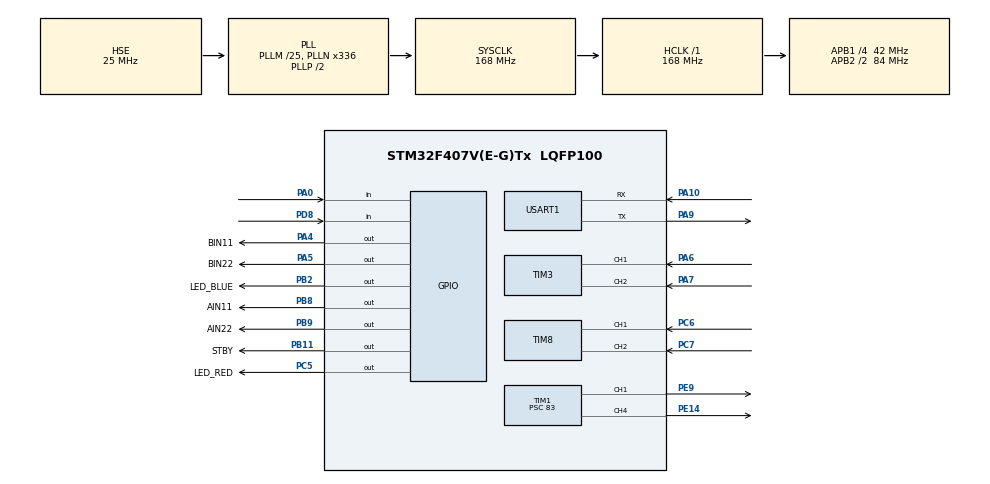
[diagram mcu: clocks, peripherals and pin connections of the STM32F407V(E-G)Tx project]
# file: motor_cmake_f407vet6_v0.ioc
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Mcu.Family=STM32F4
Mcu.Name=STM32F407V(E-G)Tx
Mcu.Package=LQFP100
NVIC.PriorityGroup=NVIC_PRIORITYGROUP_4
NVIC.TIM1_CC_IRQn=true\:0\:0\:false\:false\:true\:true\:true\:true
NVIC.TIM1_UP_TIM10_IRQn=true\:0\:0\:false\:false\:true\:true\:true\:true
NVIC.TIM3_IRQn=true\:0\:0\:false\:false\:true\:true\:true\:true
NVIC.TIM4_IRQn=true\:0\:0\:false\:false\:true\:true\:true\:true
NVIC.TIM8_BRK_TIM12_IRQn=true\:0\:0\:false\:false\:true\:true\:true\:true
NVIC.TIM8_CC_IRQn=true\:0\:0\:false\:false\:true\:true\:true\:true
NVIC.TIM8_TRG_COM_TIM14_IRQn=true\:0\:0\:false\:false\:true\:true\:true\:true
NVIC.TIM8_UP_TIM13_IRQn=true\:0\:0\:false\:false\:true\:true\:true\:true
NVIC.USART1_IRQn=true\:0\:0\:false\:false\:true\:true\:true\:true
PA0-WKUP.GPIO_PuPd=GPIO_NOPULL
PA0-WKUP.Signal=GPIO_Input
PA10.Mode=Asynchronous
PA10.Signal=USART1_RX
PA13.Mode=Serial_Wire
PA13.Signal=SYS_JTMS-SWDIO
PA14.Mode=Serial_Wire
PA14.Signal=SYS_JTCK-SWCLK
PA4.GPIO_Label=BIN11
PA4.Signal=GPIO_Output
PA5.GPIO_Label=BIN22
PA5.Signal=GPIO_Output
PA6.Signal=S_TIM3_CH1
PA7.Signal=S_TIM3_CH2
PA9.Mode=Asynchronous
PA9.Signal=USART1_TX
PB11.GPIO_Label=STBY
PB11.Signal=GPIO_Output
PB2.GPIO_Label=LED_BLUE
PB2.Signal=GPIO_Output
PB8.GPIO_Label=AIN11
PB8.Signal=GPIO_Output
PB9.GPIO_Label=AIN22
PB9.Signal=GPIO_Output
PC5.GPIO_Label=LED_RED
PC5.Signal=GPIO_Output
PC6.Signal=S_TIM8_CH1
PC7.Signal=S_TIM8_CH2
PD8.Signal=GPIO_Input
PE14.Signal=S_TIM1_CH4
PE9.Signal=S_TIM1_CH1
PH0-OSC_IN.Mode=HSE-External-Oscillator
PH0-OSC_IN.Signal=RCC_OSC_IN
PH1-OSC_OUT.Mode=HSE-External-Oscillator
PH1-OSC_OUT.Signal=RCC_OSC_OUT
ProjectManager.HeapSize=0x200
ProjectManager.StackSize=0x400
ProjectManager.TargetToolchain=CMake
RCC.48MHZClocksFreq_Value=84000000
RCC.AHBFreq_Value=168000000
RCC.APB1CLKDivider=RCC_HCLK_DIV4
RCC.APB1Freq_Value=42000000
RCC.APB1TimFreq_Value=84000000
RCC.APB2CLKDivider=RCC_HCLK_DIV2
RCC.APB2Freq_Value=84000000
RCC.APB2TimFreq_Value=168000000
RCC.CortexFreq_Value=168000000
RCC.HCLKFreq_Value=168000000
RCC.HSE_VALUE=25000000
RCC.HSI_VALUE=16000000
RCC.LSE_VALUE=32768
RCC.PLLM=25
RCC.PLLN=336
RCC.PLLSourceVirtual=RCC_PLLSOURCE_HSE
RCC.SYSCLKFreq_VALUE=168000000
RCC.SYSCLKSource=RCC_SYSCLKSOURCE_PLLCLK
RCC.VCOOutputFreq_Value=336000000
SH.S_TIM1_CH1.0=TIM1_CH1,PWM Generation1 CH1
SH.S_TIM1_CH4.0=TIM1_CH4,PWM Generation4 CH4
SH.S_TIM3_CH1.0=TIM3_CH1,Encoder_Interface
SH.S_TIM3_CH2.0=TIM3_CH2,Encoder_Interface
SH.S_TIM8_CH1.0=TIM8_CH1,Encoder_Interface
SH.S_TIM8_CH2.0=TIM8_CH2,Encoder_Interface
TIM1.AutoReloadPreload=TIM_AUTORELOAD_PRELOAD_ENABLE
TIM1.Channel-PWM\ Generation1\ CH1=TIM_CHANNEL_1
TIM1.Channel-PWM\ Generation4\ CH4=TIM_CHANNEL_4
TIM1.Period=999
TIM1.Prescaler=83
TIM3.AutoReloadPreload=TIM_AUTORELOAD_PRELOAD_ENABLE
TIM3.EncoderMode=TIM_ENCODERMODE_TI12
TIM4.Period=9999
TIM4.Prescaler=16799
TIM8.EncoderMode=TIM_ENCODERMODE_TI12
USART1.VirtualMode=VM_ASYNC
VP_TIM1_VS_ClockSourceINT.Mode=Internal
VP_TIM4_VS_ClockSourceINT.Mode=Internal
board=custom

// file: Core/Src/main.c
/* USER CODE BEGIN Header */
/**
 ******************************************************************************
 * @file           : main.c
 * @brief          : Main program body
 ******************************************************************************
 * @attention
 *
 * Copyright (c) 2025 STMicroelectronics.
 * All rights reserved.
 *
 * This software is licensed under terms that can be found in the LICENSE file
 * in the root directory of this software component.
 * If no LICENSE file comes with this software, it is provided AS-IS.
 *
 ******************************************************************************
 */
/* USER CODE END Header */
#include "main.h"
#include "tim.h"
#include "usart.h"
#include "gpio.h"

/* USER CODE BEGIN Includes */
#include "mymain.h"

/* USER CODE END Includes */

void SystemClock_Config(void);

int main(void)
{

    /* MCU Configuration--------------------------------------------------------*/

    /* Reset of all peripherals, Initializes the Flash interface and the Systick. */
    HAL_Init();

    /* Configure the system clock */
    SystemClock_Config();

    /* Initialize all configured peripherals */
    MX_GPIO_Init();
    MX_USART1_UART_Init();
    MX_TIM1_Init();
    MX_TIM3_Init();
    MX_TIM4_Init();
    MX_TIM8_Init();
    /* USER CODE BEGIN 2 */
    mymain();

    /* USER CODE END 2 */

    /* Infinite loop */
    while (1)
    {

        /* USER CODE BEGIN 3 */
        // printf("hello cmake\n");
        HAL_GPIO_TogglePin(GPIOB, GPIO_PIN_2);
        HAL_Delay(1000);
    }
    /* USER CODE END 3 */
}

void SystemClock_Config(void)
{
    RCC_OscInitTypeDef RCC_OscInitStruct = {0};
    RCC_ClkInitTypeDef RCC_ClkInitStruct = {0};

    /** Configure the main internal regulator output voltage
     */
    __HAL_RCC_PWR_CLK_ENABLE();
    __HAL_PWR_VOLTAGESCALING_CONFIG(PWR_REGULATOR_VOLTAGE_SCALE1);

    /** Initializes the RCC Oscillators according to the specified parameters
     * in the RCC_OscInitTypeDef structure.
     */
    RCC_OscInitStruct.OscillatorType = RCC_OSCILLATORTYPE_HSE;
    RCC_OscInitStruct.HSEState = RCC_HSE_ON;
    RCC_OscInitStruct.PLL.PLLState = RCC_PLL_ON;
    RCC_OscInitStruct.PLL.PLLSource = RCC_PLLSOURCE_HSE;
    RCC_OscInitStruct.PLL.PLLM = 25;
    RCC_OscInitStruct.PLL.PLLN = 336;
    RCC_OscInitStruct.PLL.PLLP = RCC_PLLP_DIV2;
    RCC_OscInitStruct.PLL.PLLQ = 4;
    if (HAL_RCC_OscConfig(&RCC_OscInitStruct) != HAL_OK)
    {
        Error_Handler();
    }

    /** Initializes the CPU, AHB and APB buses clocks
     */
    RCC_ClkInitStruct.ClockType = RCC_CLOCKTYPE_HCLK | RCC_CLOCKTYPE_SYSCLK | RCC_CLOCKTYPE_PCLK1 | RCC_CLOCKTYPE_PCLK2;
    RCC_ClkInitStruct.SYSCLKSource = RCC_SYSCLKSOURCE_PLLCLK;
    RCC_ClkInitStruct.AHBCLKDivider = RCC_SYSCLK_DIV1;
    RCC_ClkInitStruct.APB1CLKDivider = RCC_HCLK_DIV4;
    RCC_ClkInitStruct.APB2CLKDivider = RCC_HCLK_DIV2;

    if (HAL_RCC_ClockConfig(&RCC_ClkInitStruct, FLASH_LATENCY_5) != HAL_OK)
    {
        Error_Handler();
    }
}

void Error_Handler(void)
{
    __disable_irq();
    while (1)
    {
    }
}
